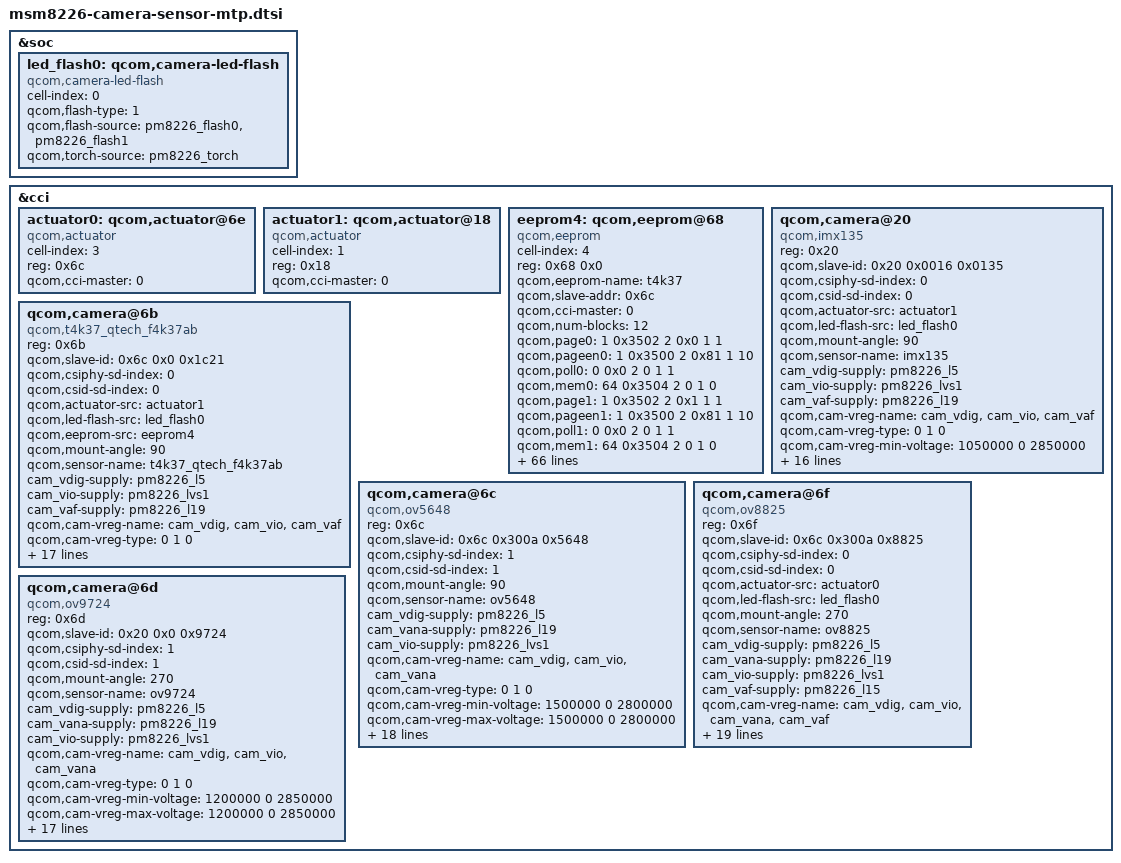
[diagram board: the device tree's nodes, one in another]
/*
 * Copyright (c) 2013, The Linux Foundation. All rights reserved.
 *
 * This program is free software; you can redistribute it and/or modify
 * it under the terms of the GNU General Public License version 2 and
 * only version 2 as published by the Free Software Foundation.
 *
 * This program is distributed in the hope that it will be useful,
 * but WITHOUT ANY WARRANTY; without even the implied warranty of
 * MERCHANTABILITY or FITNESS FOR A PARTICULAR PURPOSE.  See the
 * GNU General Public License for more details.
 */

&soc {

	led_flash0: qcom,camera-led-flash {
		cell-index = <0>;
		compatible = "qcom,camera-led-flash";
		qcom,flash-type = <1>;
		qcom,flash-source = <&pm8226_flash0 &pm8226_flash1>;
		qcom,torch-source = <&pm8226_torch>;
	};
};

&cci {

	actuator0: qcom,actuator@6e {
		cell-index = <3>;
		reg = <0x6c>;
		compatible = "qcom,actuator";
		qcom,cci-master = <0>;
	};

	actuator1: qcom,actuator@18 {
		cell-index = <1>;
		reg = <0x18>;
		compatible = "qcom,actuator";
		qcom,cci-master = <0>;
	};

	eeprom4: qcom,eeprom@68 {
		cell-index = <4>;
		reg = <0x68 0x0>;
		qcom,eeprom-name = "t4k37";
		compatible = "qcom,eeprom";
		qcom,slave-addr = <0x6c>;
		qcom,cci-master = <0>;
		//qcom,num-blocks = <5>;
		qcom,num-blocks = <12>;
		qcom,page0 = <1 0x3502 2 0x0 1 1>;
		qcom,pageen0 = <1 0x3500 2 0x81 1 10>;
		qcom,poll0 = <0 0x0 2 0 1 1>;
		qcom,mem0 = <64 0x3504 2 0 1 0>;
		qcom,page1 = <1 0x3502 2 0x1 1 1>;
		qcom,pageen1 = <1 0x3500 2 0x81 1 10>;
		qcom,poll1 = <0 0x0 2 0 1 1>;
		qcom,mem1 = <64 0x3504 2 0 1 0>;
		qcom,page2 = <1 0x3502 2 0x2 1 1>;
		qcom,pageen2 = <1 0x3500 2 0x81 1 10>;
		qcom,poll2 = <0 0x0 2 0 1 1>;
		qcom,mem2 = <64 0x3504 2 0 1 0>;
		qcom,page3 = <1 0x3502 2 0x3 1 1>;
		qcom,pageen3 = <1 0x3500 2 0x81 1 10>;
		qcom,poll3 = <0 0x0 2 0 1 1>;
		qcom,mem3 = <64 0x3504 2 0 1 0>;
		qcom,page4 = <1 0x3502 2 0x4 1 1>;
		qcom,pageen4 = <1 0x3500 2 0x81 1 10>;
		qcom,poll4 = <0 0x0 2 0 1 1>;
		qcom,mem4 = <64 0x3504 2 0 1 0>;	
		qcom,page5 = <1 0x3502 2 0x5 1 1>;  //add by jun for page 5
		qcom,pageen5 = <1 0x3500 2 0x81 1 10>;
		qcom,poll5= <0 0x0 2 0 1 1>;
		qcom,mem5 = <64 0x3504 2 0 1 0>;	//end for page 5	
		qcom,page6 = <1 0x3502 2 0x6 1 1>;  //add by jun for page 6
		qcom,pageen6 = <1 0x3500 2 0x81 1 10>;
		qcom,poll6= <0 0x0 2 0 1 1>;
		qcom,mem6 = <64 0x3504 2 0 1 0>;	//end for page 6	
		qcom,page7 = <1 0x3502 2 0x7 1 1>;  //add by jun for page 7
		qcom,pageen7 = <1 0x3500 2 0x81 1 10>;
		qcom,poll7= <0 0x0 2 0 1 1>;
		qcom,mem7 = <64 0x3504 2 0 1 0>;	//end for page 7	
		qcom,page8 = <1 0x3502 2 0x8 1 1>;  //add by jun for page 8
		qcom,pageen8 = <1 0x3500 2 0x81 1 10>;
		qcom,poll8= <0 0x0 2 0 1 1>;
		qcom,mem8 = <64 0x3504 2 0 1 0>;	//end for page 8	
		qcom,page9 = <1 0x3502 2 0x9 1 1>;  //add by jun for page 9
		qcom,pageen9 = <1 0x3500 2 0x81 1 10>;
		qcom,poll9= <0 0x0 2 0 1 1>;
		qcom,mem9 = <64 0x3504 2 0 1 0>;	//end for page 9		
		qcom,page10 = <1 0x3502 2 0xa 1 1>;  //add by jun for page 10
		qcom,pageen10 = <1 0x3500 2 0x81 1 10>;
		qcom,poll10= <0 0x0 2 0 1 1>;
		qcom,mem10 = <64 0x3504 2 0 1 0>;	//end for page 10	
		qcom,page11 = <1 0x3502 2 0xb 1 1>;  //add by jun for page 11
		qcom,pageen11 = <1 0x3500 2 0x81 1 10>;
		qcom,poll11= <0 0x0 2 0 1 1>;
		qcom,mem11 = <64 0x3504 2 0 1 0>;	//end for page 11	
		cam_vdig-supply = <&pm8226_l5>;
		cam_vana-supply = <&pm8226_l19>;  //add for camera avdd
		cam_vio-supply = <&pm8226_lvs1>;
		qcom,cam-vreg-name = "cam_vdig", "cam_vio", "cam_vana";
		qcom,cam-vreg-type = <0 1 0>;
		qcom,cam-vreg-min-voltage = <1200000 0 2850000>;
		qcom,cam-vreg-max-voltage = <1200000 0 2850000>;
		qcom,cam-vreg-op-mode = <200000 0 100000>;
		qcom,gpio-no-mux = <0>;
		gpios = <&msmgpio 26 0>,
			<&msmgpio 37 0>,
			<&msmgpio 36 0>;
		qcom,gpio-avdd-enable = <&msmgpio 14 0>;		
		qcom,gpio-reset = <1>;
		qcom,gpio-standby = <2>;
		qcom,gpio-req-tbl-num = <0 1 2>;
		qcom,gpio-req-tbl-flags = <1 0 0>;
		qcom,gpio-req-tbl-label = "CAMIF_MCLK",
			"CAM_RESET1",
			"CAM_STANDBY";
		qcom,cam-power-seq-type =  "sensor_clk",
			"sensor_gpio", "sensor_gpio", "sensor_gpio", "sensor_gpio";
		qcom,cam-power-seq-val =  "sensor_cam_mclk","sensor_gpio_standby",
			"sensor_gpio_reset",
			"sensor_gpio_standby","sensor_gpio_reset";
		qcom,cam-power-seq-cfg-val = <24000000 0 0 1 1>;
		qcom,cam-power-seq-delay = <10 10 2 10 2>;
	};


	qcom,camera@20 {
		compatible = "qcom,imx135";
		reg = <0x20>;
		qcom,slave-id = <0x20 0x0016 0x0135>;
		qcom,csiphy-sd-index = <0>;
		qcom,csid-sd-index = <0>;
		qcom,actuator-src = <&actuator1>;
		qcom,led-flash-src = <&led_flash0>;
		qcom,mount-angle = <90>;
		qcom,sensor-name = "imx135";
		cam_vdig-supply = <&pm8226_l5>;
		/*cam_vana-supply = <&pm8226_l19>;*/
		cam_vio-supply = <&pm8226_lvs1>;
		cam_vaf-supply = <&pm8226_l19>;
		qcom,cam-vreg-name = "cam_vdig", "cam_vio", /*"cam_vana",*/
							 "cam_vaf";
		qcom,cam-vreg-type = <0 1  0>;
		qcom,cam-vreg-min-voltage = <1050000 0  2850000>;
		qcom,cam-vreg-max-voltage = <1050000 0  2850000>;
		qcom,cam-vreg-op-mode = <200000 0  100000>;
		qcom,gpio-no-mux = <0>;
		gpios = <&msmgpio 26 0>,
			<&msmgpio 37 0>,
			<&msmgpio 36 0>;
		qcom,gpio-reset = <1>;
		qcom,gpio-standby = <2>;
		qcom,gpio-req-tbl-num = <0 1 2>;
		qcom,gpio-req-tbl-flags = <1 0 0>;
		qcom,gpio-req-tbl-label = "CAMIF_MCLK",
			"CAM_RESET1",
			"CAM_STANDBY";
		qcom,gpio-avdd-enable = <&msmgpio 14 0>;		/*tanyijun add for back camera avdd enable */	
		qcom,csi-lane-assign = <0x4320>;
		qcom,csi-lane-mask = <0x1f>;
		qcom,sensor-position = <0>;
		qcom,sensor-mode = <1>;
		qcom,cci-master = <0>;
		status = "ok";
	};

		qcom,camera@6b {
		compatible = "qcom,t4k37_qtech_f4k37ab";
		reg = <0x6b>;
		qcom,slave-id = <0x6c 0x0 0x1c21>;
		qcom,csiphy-sd-index = <0>;
		qcom,csid-sd-index = <0>;
		qcom,actuator-src = <&actuator1>;
		qcom,led-flash-src = <&led_flash0>;
		qcom,eeprom-src = <&eeprom4>;
		qcom,mount-angle = <90>;
		qcom,sensor-name = "t4k37_qtech_f4k37ab";
		cam_vdig-supply = <&pm8226_l5>;
		/*cam_vana-supply = <&pm8226_l19>;*/
		cam_vio-supply = <&pm8226_lvs1>;
		cam_vaf-supply = <&pm8226_l19>;
		qcom,cam-vreg-name = "cam_vdig", "cam_vio", /*"cam_vana",*/
							 "cam_vaf";
		qcom,cam-vreg-type = <0 1  0>;
		qcom,cam-vreg-min-voltage = <1200000 0  2850000>;
		qcom,cam-vreg-max-voltage = <1200000 0  2850000>;
		qcom,cam-vreg-op-mode = <200000 0  100000>;
		qcom,gpio-no-mux = <0>;
		gpios = <&msmgpio 26 0>,
			<&msmgpio 37 0>,
			<&msmgpio 36 0>;
		qcom,gpio-reset = <1>;
		qcom,gpio-standby = <2>;
		qcom,gpio-req-tbl-num = <0 1 2>;
		qcom,gpio-req-tbl-flags = <1 0 0>;
		qcom,gpio-req-tbl-label = "CAMIF_MCLK",
			"CAM_RESET1",
			"CAM_STANDBY";
		qcom,gpio-avdd-enable = <&msmgpio 14 0>;		/*tanyijun add for back camera avdd enable */	
		qcom,csi-lane-assign = <0x4320>;
		qcom,csi-lane-mask = <0x1f>;
		qcom,sensor-position = <0>;
		qcom,sensor-mode = <1>;
		qcom,cci-master = <0>;
		status = "ok";
	};
	qcom,camera@6c {
		compatible = "qcom,ov5648";
		reg = <0x6c>;
		qcom,slave-id = <0x6c 0x300a 0x5648>;
		qcom,csiphy-sd-index = <1>;
		qcom,csid-sd-index = <1>;
		qcom,mount-angle = <90>;
		qcom,sensor-name = "ov5648";
		cam_vdig-supply = <&pm8226_l5>;
		cam_vana-supply = <&pm8226_l19>;
		cam_vio-supply = <&pm8226_lvs1>;
		qcom,cam-vreg-name = "cam_vdig", "cam_vio", "cam_vana";
		qcom,cam-vreg-type = <0 1 0>;
		qcom,cam-vreg-min-voltage = <1500000 0 2800000>;
		qcom,cam-vreg-max-voltage = <1500000 0 2800000>;
		qcom,cam-vreg-op-mode = <200000 0 80000>;
		qcom,gpio-no-mux = <0>;
		gpios = <&msmgpio 26 0>,
				<&msmgpio 28 0>,
				<&msmgpio 35 0>;
		qcom,gpio-reset = <1>;
		qcom,gpio-standby = <2>;
		qcom,gpio-req-tbl-num = <0 1 2>;
		qcom,gpio-req-tbl-flags = <1 0 0>;
		qcom,gpio-req-tbl-label = "CAMIF_MCLK",
				"CAM_RESET",
				"CAM_STANDBY";
		qcom,gpio-avdd-enable = <&msmgpio 12 0>;		/*tanyijun add for back camera avdd enable */				
		qcom,gpio-set-tbl-num = <1 1>;
		qcom,gpio-set-tbl-flags = <0 2>;
		qcom,gpio-set-tbl-delay = <1000 4000>;
		qcom,csi-lane-assign = <0x4320>;
		qcom,csi-lane-mask = <0x3>;
		qcom,sensor-position = <1>;
		qcom,sensor-mode = <1>;
		qcom,cci-master = <0>;
		status = "ok";
	};

	qcom,camera@6f {
		compatible = "qcom,ov8825";
		reg = <0x6f>;
		qcom,slave-id = <0x6c 0x300a 0x8825>;
		qcom,csiphy-sd-index = <0>;
		qcom,csid-sd-index = <0>;
		qcom,actuator-src = <&actuator0>;
		qcom,led-flash-src = <&led_flash0>;
		qcom,mount-angle = <270>;
		qcom,sensor-name = "ov8825";
		cam_vdig-supply = <&pm8226_l5>;
		cam_vana-supply = <&pm8226_l19>;
		cam_vio-supply = <&pm8226_lvs1>;
		cam_vaf-supply = <&pm8226_l15>;
		qcom,cam-vreg-name = "cam_vdig", "cam_vio", "cam_vana",
							 "cam_vaf";
		qcom,cam-vreg-type = <0 1 0 0>;
		qcom,cam-vreg-min-voltage = <1200000 0 2850000 2800000>;
		qcom,cam-vreg-max-voltage = <1200000 0 2850000 2800000>;
		qcom,cam-vreg-op-mode = <200000 0 80000 100000>;
		qcom,gpio-no-mux = <0>;
		gpios = <&msmgpio 26 0>,
			<&msmgpio 37 0>,
			<&msmgpio 35 0>;
		qcom,gpio-reset = <1>;
		qcom,gpio-standby = <2>;
		qcom,gpio-req-tbl-num = <0 1 2>;
		qcom,gpio-req-tbl-flags = <1 0 0>;
		qcom,gpio-req-tbl-label = "CAMIF_MCLK",
			"CAM_RESET1",
			"CAM_STANDBY";
		qcom,csi-lane-assign = <0x4320>;
		qcom,csi-lane-mask = <0x1f>;
		qcom,sensor-position = <0>;
		qcom,sensor-mode = <1>;
		qcom,cci-master = <0>;
	};

	qcom,camera@6d {
		compatible = "qcom,ov9724";
		reg = <0x6d>;
		qcom,slave-id = <0x20 0x0 0x9724>;
		qcom,csiphy-sd-index = <1>;
		qcom,csid-sd-index = <1>;
		qcom,mount-angle = <270>;
		qcom,sensor-name = "ov9724";
		cam_vdig-supply = <&pm8226_l5>;
		cam_vana-supply = <&pm8226_l19>;
		cam_vio-supply = <&pm8226_lvs1>;
		qcom,cam-vreg-name = "cam_vdig", "cam_vio", "cam_vana";
		qcom,cam-vreg-type = <0 1 0>;
		qcom,cam-vreg-min-voltage = <1200000 0 2850000>;
		qcom,cam-vreg-max-voltage = <1200000 0 2850000>;
		qcom,cam-vreg-op-mode = <200000 0 80000>;
		qcom,gpio-no-mux = <0>;
		gpios = <&msmgpio 26 0>,
				<&msmgpio 28 0>,
				<&msmgpio 36 0>;
		qcom,gpio-reset = <1>;
		qcom,gpio-standby = <2>;
		qcom,gpio-req-tbl-num = <0 1 2>;
		qcom,gpio-req-tbl-flags = <1 0 0>;
		qcom,gpio-req-tbl-label = "CAMIF_MCLK",
				"CAM_RESET",
				"CAM_STANDBY";
		qcom,gpio-set-tbl-num = <1 1>;
		qcom,gpio-set-tbl-flags = <0 2>;
		qcom,gpio-set-tbl-delay = <1000 4000>;
		qcom,csi-lane-assign = <0x4320>;
		qcom,csi-lane-mask = <0x3>;
		qcom,sensor-position = <1>;
		qcom,sensor-mode = <1>;
		qcom,cci-master = <0>;
		status = "ok";
	};
};
